AUTOSAR XML (schema 00044)
package /ComponentTypes
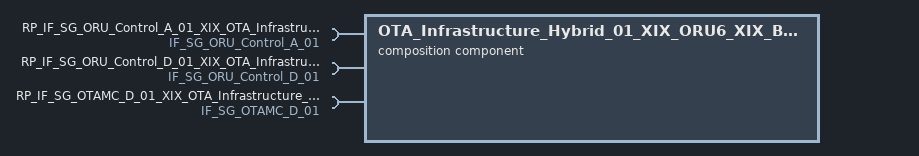
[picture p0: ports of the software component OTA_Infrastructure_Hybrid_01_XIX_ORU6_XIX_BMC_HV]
  composition sw component type OTA_Infrastructure_Hybrid_01_XIX_ORU6_XIX_BMC_HV
    require port RP_IF_SG_ORU_Control_A_01_XIX_OTA_Infrastructure_Hybrid_01_XIX_ORU6_XIX_BMC_HV: nonqueued-receiver-com-spec=DE_SG_ORU_Control_A_01, required-interface=IF_SG_ORU_Control_A_01
    require port RP_IF_SG_ORU_Control_D_01_XIX_OTA_Infrastructure_Hybrid_01_XIX_ORU6_XIX_BMC_HV: nonqueued-receiver-com-spec=DE_SG_ORU_Control_D_01, required-interface=IF_SG_ORU_Control_D_01
    require port RP_IF_SG_OTAMC_D_01_XIX_OTA_Infrastructure_Hybrid_01_XIX_ORU6_XIX_BMC_HV: nonqueued-receiver-com-spec=DE_SG_OTAMC_D_01, required-interface=IF_SG_OTAMC_D_01
